# PRUSS1_UART register map
Vendor: Texas Instruments
Peripheral module from a debugger description file (folder DRA72x).
Registers are 32-bit, access per field, reset values left out (the file's numbers can be read two ways) unless marked. A register's access mark holds for its fields unless they carry their own. Offsets are as the file gives them; lines under a group give offsets from that group; [hi:lo] are bit positions; {n}, {i} and the like mark numbered series; 'fields as' and 'values as' point back to an identical list; <NAME> marks a mode.

## PRUSS1_UART
0x00 PRUSS_UART_RBR_THR_REGISTERS — In the non-FIFO mode, when a character is placed in Receiver buffer register and the receiver data-ready interrupt is enabled (DR = 1 in Interrupt identification register), an interrupt is generated. This interrupt is cleared when the character is read from Receiver buffer register. In the FIFO mode, the interrupt is generated when the FIFO is filled to the trigger level selected in the FIFO control register, and it is cleared when the FIFO contents drop below the trigger level. In the non-FIFO mode, if Transmitter holding register is empty and the THR empty (THRE) interrupt is enabled (ETBEI = 1 in Interrupt enable register), an interrupt is generated. This interrupt is cleared when a character is loaded into Transmitter holding register or the Interrupt identification register is read. In the FIFO mode, the interrupt is generated when the transmitter FIFO is empty, and it is cleared when at least one byte is loaded into the FIFO or Interrupt identification register is read.
  [7:0] DATA rw — Read: Read Receive Buffer RegisterWrite: Write Transmitter Holding Register .
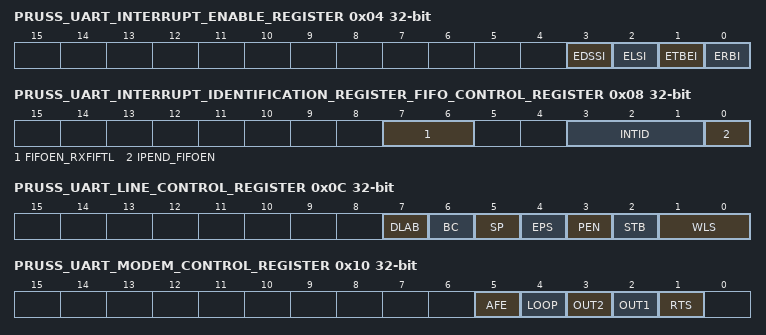
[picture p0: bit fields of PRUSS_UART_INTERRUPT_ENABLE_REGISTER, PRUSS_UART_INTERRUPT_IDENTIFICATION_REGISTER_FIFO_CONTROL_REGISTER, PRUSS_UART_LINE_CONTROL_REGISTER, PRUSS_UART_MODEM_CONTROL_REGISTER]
0x04 PRUSS_UART_INTERRUPT_ENABLE_REGISTER — The Interrupt enable register is used to individually enable or disable each type of interrupt request that can be generated by the UART. Each interrupt request that is enabled in Interrupt enable register is forwarded to the CPU.
  [3] EDSSI rw — Enable Modem Status Interrupt
  [2] ELSI rw — Receiver line status interrupt enable.
    0=DIS (Receiver line status interrupt is disabled.); 1=EN (Receiver line status interrupt is enabled.)
  [1] ETBEI rw — Transmitter holding register empty interrupt enable.
    0=DIS (Transmitter holding register empty interrupt is disabled.); 1=EN (Transmitter holding register empty interrupt is enabled.)
  [0] ERBI rw — Receiver data available interrupt and character timeout indication interrupt enable.
    0=DIS (Receiver data available interrupt and character timeout indication interrupt is disabled.); 1=EN (Receiver data available interrupt and character timeout indication interrupt is enabled.)
0x08 PRUSS_UART_INTERRUPT_IDENTIFICATION_REGISTER_FIFO_CONTROL_REGISTER — The Interrupt identification register is a read-only register at the same address as the FIFO control register, which is a write-only register. When an interrupt is generated and enabled in the Interrupt enable register, Interrupt identification register indicates that an interrupt is pending in the IPEND bit and encodes the type of interrupt in the INTID bits. Reading Interrupt identification register clears any THR empty (THRE) interrupts that are pending. The FIFOEN bit in Interrupt identification register can be checked to determine whether the UART is in the FIFO mode or the non-FIFO mode. Use FIFO control register to enable and clear the FIFOs and to select the receiver FIFO trigger level. The FIFOEN bit in FIFO control register must be set to 1 before other FIFO control register bits are written to or the FIFO control register bits are not programmed.
  [7:6] FIFOEN_RXFIFTL rw — Read: FIFOs enabled.0x1-0x2: Reserved . Write: Receiver FIFO trigger level. RXFIFTL sets the trigger level for the receiver FIFO. When the trigger level is reached, a receiver data-ready interrupt is generated (if the interrupt request is enabled). Once the FIFO drops below the trigger level, the interrupt is cleared. .
    0=Non-FIFO_mode; 3=FIFOEN_FIFO_(FCR)_3 (FIFOs are enabled. FIFOEN bit in the FIFO control register (FCR) is set to 1.); 0=1_byte; 1=4_bytes; 2=8_bytes; 3=14_bytes
  [3:1] INTID rw — Read: Interrupt type. See .0x4-0x5: Reserved . Write: . Bit 3: DMAMODE1: DMA MODE1 enable if FIFOs are enabled. Always write 1 to DMAMODE1. After a hardware reset, change DMAMODE1 from 0 to 1. DMAMODE1 = 1 is a requirement for proper communication between the UART and the EDMA controller. . Bit 2: TXCLR: Transmitter FIFO clear. Write a 1 to TXCLR to clear the bit. . Bit 1: RXCLR: Receiver FIFO clear. Write a 1 to RXCLR to clear the bit. .
    1=Transmitter holding register empty (priority 3); 2=Receiver_data_available_(priority_2); 3=Receiver line status (priority 1, highest); 6=Character timeout indication (priority 2); 0=DIS (DMA MODE1 is disabled.); 1=EN (DMA MODE1 is enabled.); 0=No_effect; 1=FIFO_FIFO_1 (Clears transmitter FIFO and resets the transmitter FIFO counter. The shift register is not cleared.); 0=No_effect; 1=FIFO_FIFO_1 (Clears receiver FIFO and resets the receiver FIFO counter. The shift register is not cleared.)
  [0] IPEND_FIFOEN rw — Read: Interrupt pending. When any UART interrupt is generated and is enabled in IER, IPEND is forced to 0. IPEND remains 0 until all pending interrupts are cleared or until a hardware reset occurs. If no interrupts are enabled, IPEND is never forced to 0.Write: Transmitter and receiver FIFOs mode enable. FIFOEN must be set before other FCR bits are written to or the FCR bits are not programmed. Clearing this bit clears the FIFO counters. .
    0=Interrupts_pending; 1=No_interrupts_pending; 0=FIFO_0 (Non-FIFO mode. The transmitter and receiver FIFOs are disabled, and the FIFO pointers are cleared.); 1=FIFO_1 (FIFO mode. The transmitter and receiver FIFOs are enabled.)
0x0C PRUSS_UART_LINE_CONTROL_REGISTER — The system programmer controls the format of the asynchronous data communication exchange by using Line control register. In addition, the programmer can retrieve, inspect, and modify the content of line control register; this eliminates the need for separate storage of the line characteristics in system memory.
  [7] DLAB rw — Divisor latch access bit. The divisor latch registers (DLL and DLH) can be accessed at dedicated addresses or at addresses shared by RBR, THR, and IER. Using the shared addresses requires toggling DLAB to change which registers are selected. If you use the dedicated addresses, you can keep DLAB = 0.
    0=(RBR),_(THR),_(IER)_RBR,_THR,_DLL,_CPU_RBR_THR._IER_DLH,_CPU_IER._0 (Allows access to the receiver buffer register (RBR), the transmitter holding register (THR), and the interrupt enable register (IER) selected. At the address shared by RBR, THR, and DLL, the CPU can read from RBR and write to THR. At the address shared by IER and DLH, the CPU can read from and write to IER.); 1=(DLL_DLH)._RBR,_THR,_DLL,_CPU_DLL._IER_DLH,_CPU_DLH._1 (Allows access to the divisor latches of the baud generator during a read or write operation (DLL and DLH). At the address shared by RBR, THR, and DLL, the CPU can read from and write to DLL. At the address shared by IER and DLH, the CPU can read from and write to DLH.)
  [6] BC rw — Break control.
    0=DIS (Break condition is disabled.); 1=EN (Break condition is transmitted to the receiving UART. A break condition is a condition where the UARTn_TXD signal is forced to the spacing (cleared) state.)
  [5] SP rw — Stick parity. The SP bit works in conjunction with the EPS and PEN bits. The relationship between the SP, EPS, and PEN bits is summarized in.
    0=DIS (Stick parity is disabled.); 1=EN (Stick parity is enabled.)
  [4] EPS rw — Even parity select. Selects the parity when parity is enabled (PEN = 1). The EPS bit works in conjunction with the SP and PEN bits. The relationship between the SP, EPS, and PEN bits is summarized in.
    0=PARITY_0 (Odd parity is selected (an odd number of logic 1s is transmitted or checked in the data and PARITY bits).); 1=PARITY_1 (Even parity is selected (an even number of logic 1s is transmitted or checked in the data and PARITY bits).)
  [3] PEN rw — Parity enable. The PEN bit works in conjunction with the SP and EPS bits. The relationship between the SP, EPS, and PEN bits is summarized in.
    0=PARITY_0 (No PARITY bit is transmitted or checked.); 1=STOP_1 (Parity bit is generated in transmitted data and is checked in received data between the last data word bit and the first STOP bit.)
  [2] STB rw — Number of STOP bits generated. STB specifies 1, 1.5, or 2 STOP bits in each transmitted character. When STB = 1, the WLS bit determines the number of STOP bits. The receiver clocks only the first STOP bit, regardless of the number of STOP bits selected. The number of STOP bits generated is summarized in.
    0=1_STOP_bit_is_generated; 1=WLS_STOP_1 (WLS bit determines the number of STOP bits:)
  [1:0] WLS rw — Word length select. Number of bits in each transmitted or received serial character. When STB = 1, the WLS bit determines the number of STOP bits.
    {v}={v+5}_bits (v=0..3)
0x10 PRUSS_UART_MODEM_CONTROL_REGISTER — The Modem control register provides the ability to enable/disable the autoflow functions, and enable/disable the loopback function for diagnostic purposes.
  [5] AFE rw — Autoflow control enable. Autoflow control allows the and signals to provide handshaking between UARTs during data transfer. When AFE = 1, the RTS bit determines the autoflow control enabled. Note that all UARTs do not support this feature, see your device-specific data manual for supported features. If this feature is not available, this bit is reserved in this device and should be cleared to 0.
    0=DIS (Autoflow control is disabled.); 1=EN (Autoflow control is enabled:)
  [4] LOOP rw — Loop back mode enable. LOOP is used for the diagnostic testing using the loop back feature.
    0=DIS (Loop back mode is disabled.); 1=EN (Loop back mode is enabled. When LOOP is set, the following occur:)
  [3] OUT2 rw — OUT2 Control Bit
  [2] OUT1 rw — OUT1 Control Bit
  [1] RTS rw — RTS control. When AFE = 1, the RTS bit determines the autoflow control enabled. Note that all UARTs do not support this feature, see your device-specific data manual for supported features. If this feature is not available, this bit is reserved in this device and should be cleared to 0.
    0=DIS (UARTn_RTS is disabled, UARTn_CTS is only enabled.); 1=EN (UARTn_RTS and UARTn_CTS are enabled.)
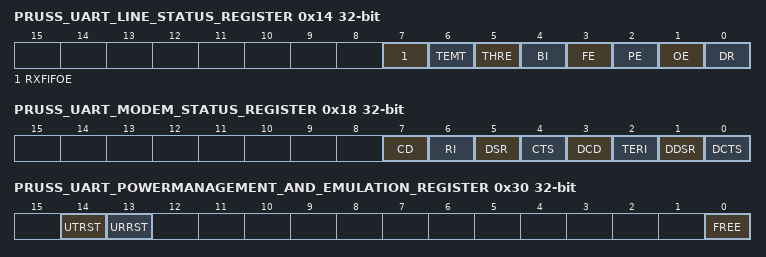
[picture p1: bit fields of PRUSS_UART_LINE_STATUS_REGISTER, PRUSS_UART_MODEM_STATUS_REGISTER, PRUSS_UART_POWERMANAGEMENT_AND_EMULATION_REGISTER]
0x14 PRUSS_UART_LINE_STATUS_REGISTER ro — The Line status register provides information to the CPU concerning the status of data transfers. Line status register is intended for read operations only; do not write to this register. Bits 1 through 4 record the error conditions that produce a receiver line status interrupt.
  [7] RXFIFOE — Receiver FIFO error. In non-FIFO mode:In FIFO mode: .
    0=RXFIFOE_CPU_(RBR)._0 (There has been no error, or RXFIFOE was cleared because the CPU read the erroneous character from the receiver buffer register (RBR).); 1=(RBR)._1 (There is a parity error, framing error, or break indicator in the receiver buffer register (RBR).); 0=RXFIFOE_CPU_FIFO_FIFO._0 (There has been no error, or RXFIFOE was cleared because the CPU read the erroneous character from the receiver FIFO and there are no more errors in the receiver FIFO.); 1=FIFO._1 (At least one parity error, framing error, or break indicator in the receiver FIFO.)
  [6] TEMT — Transmitter empty (TEMT) indicator. In non-FIFO mode:In FIFO mode: .
    0=(THR)_(TSR)_0 (Either the transmitter holding register (THR) or the transmitter shift register (TSR) contains a data character.); 1=(THR)_(TSR)_1 (Both the transmitter holding register (THR) and the transmitter shift register (TSR) are empty.); 0=FIFO_(TSR)_0 (Either the transmitter FIFO or the transmitter shift register (TSR) contains a data character.); 1=FIFO_(TSR)_1 (Both the transmitter FIFO and the transmitter shift register (TSR) are empty.)
  [5] THRE — Transmitter holding register empty (THRE) indicator. If the THRE bit is set and the corresponding interrupt enable bit is set (ETBEI = 1 in IER), an interrupt request is generated. In non-FIFO mode:In FIFO mode: .
    0=(THR)_THR_CPU._0 (Transmitter holding register (THR) is not empty. THR has been loaded by the CPU.); 1=(THR)_THR_(TSR)._1 (Transmitter holding register (THR) is empty (ready to accept a new character). The content of THR has been transferred to the transmitter shift register (TSR).); 0=FIFO_FIFO._FIFO_0 (Transmitter FIFO is not empty. At least one character has been written to the transmitter FIFO. You can write to the transmitter FIFO if it is not full.); 1=FIFO_FIFO_(TSR)._1 (Transmitter FIFO is empty. The last character in the FIFO has been transferred to the transmitter shift register (TSR).)
  [4] BI — Break indicator. The BI bit is set whenever the receive data input (UARTn_RXD) was held low for longer than a full-word transmission time. A full-word transmission time is defined as the total time to transmit the START, data, PARITY, and STOP bits. If the BI bit is set and the corresponding interrupt enable bit is set (ELSI = 1 in IER), an interrupt request is generated. In non-FIFO mode:In FIFO mode: .
    0=BI_CPU_(RBR)._0 (No break has been detected, or the BI bit was cleared because the CPU read the erroneous character from the receiver buffer register (RBR).); 1=A_(RBR)._1 (A break has been detected with the character in the receiver buffer register (RBR).); 0=BI_CPU_FIFO_FIFO_0 (No break has been detected, or the BI bit was cleared because the CPU read the erroneous character from the receiver FIFO and the next character to be read from the FIFO has no break indicator.); 1=A_FIFO._1 (A break has been detected with the character at the top of the receiver FIFO.)
  [3] FE — Framing error (FE) indicator. A framing error occurs when the received character does not have a valid STOP bit. In response to a framing error, the UART sets the FE bit and waits until the signal on the RX pin goes high. Once the RX signal goes high, the receiver is ready to detect a new START bit and receive new data. If the FE bit is set and the corresponding interrupt enable bit is set (ELSI = 1 in IER), an interrupt request is generated. In non-FIFO mode:In FIFO mode: .
    0=FE_CPU_(RBR)._0 (No framing error has been detected, or the FE bit was cleared because the CPU read the erroneous data from the receiver buffer register (RBR).); 1=A_(RBR)._1 (A framing error has been detected with the character in the receiver buffer register (RBR).); 0=FE_CPU_FIFO_FIFO_0 (No framing error has been detected, or the FE bit was cleared because the CPU read the erroneous data from the receiver FIFO and the next character to be read from the FIFO has no framing error.); 1=A_FIFO._1 (A framing error has been detected with the character at the top of the receiver FIFO.)
  [2] PE — Parity error (PE) indicator. A parity error occurs when the parity of the received character does not match the parity selected with the EPS bit in the line control register (LCR). If the PE bit is set and the corresponding interrupt enable bit is set (ELSI = 1 in IER), an interrupt request is generated. In non-FIFO mode:In FIFO mode: .
    0=PE_CPU_(RBR)._0 (No parity error has been detected, or the PE bit was cleared because the CPU read the erroneous data from the receiver buffer register (RBR).); 1=A_(RBR)._1 (A parity error has been detected with the character in the receiver buffer register (RBR).); 0=PE_CPU_FIFO_FIFO_0 (No parity error has been detected, or the PE bit was cleared because the CPU read the erroneous data from the receiver FIFO and the next character to be read from the FIFO has no parity error.); 1=A_FIFO._1 (A parity error has been detected with the character at the top of the receiver FIFO.)
  [1] OE — Overrun error (OE) indicator. An overrun error in the non-FIFO mode is different from an overrun error in the FIFO mode. If the OE bit is set and the corresponding interrupt enable bit is set (ELSI = 1 in IER), an interrupt request is generated. In non-FIFO mode:In FIFO mode: .
    0=OE_CPU_(LSR)._0 (No overrun error has been detected, or the OE bit was cleared because the CPU read the content of the line status register (LSR).); 1=(RBR)_RBR._1 (Overrun error has been detected. Before the character in the receiver buffer register (RBR) could be read, it was overwritten by the next character arriving in RBR.); 0=OE_CPU_(LSR)._0 (No overrun error has been detected, or the OE bit was cleared because the CPU read the content of the line status register (LSR).); 1=FIFO_FIFO_CPU_FIFO._1 (Overrun error has been detected. If data continues to fill the FIFO beyond the trigger level, an overrun error occurs only after the FIFO is full and the next character has been completely received in the shift register. An overrun error is indicated to the CPU as soon as it happens. The new character overwrites the character in the shift register, but it is not transferred to the FIFO.)
  [0] DR — Data-ready (DR) indicator for the receiver. If the DR bit is set and the corresponding interrupt enable bit is set (ERBI = 1 in IER), an interrupt request is generated. In non-FIFO mode:In FIFO mode: .
    0=DR_(RBR)._0 (Data is not ready, or the DR bit was cleared because the character was read from the receiver buffer register (RBR).); 1=A_(RBR)._1 (Data is ready. A complete incoming character has been received and transferred into the receiver buffer register (RBR).); 0=DR_FIFO_0 (Data is not ready, or the DR bit was cleared because all of the characters in the receiver FIFO have been read.); 1=FIFO._FIFO_DR_FIFO._DR_FIFO_1 (Data is ready. There is at least one unread character in the receiver FIFO. If the FIFO is empty, the DR bit is set as soon as a complete incoming character has been received and transferred into the FIFO. The DR bit remains set until the FIFO is empty again.)
0x18 PRUSS_UART_MODEM_STATUS_REGISTER ro — The Modem status register provides information to the CPU concerning the status of modem control signals. Modem status register is intended for read operations only; do not write to this register.
  [7] CD — Complement of the Carrier Detect input. When the UART is in the diagnostic test mode (loopback mode MCR[4] = 1), this bit is equal to the MCR bit 3 (OUT2).
  [6] RI — Complement of the Ring Indicator input. When the UART is in the diagnostic test mode (loopback mode MCR[4] = 1), this bit is equal to the MCR bit 2 (OUT1).
  [5] DSR — Complement of the Data Set Ready input. When the UART is in the diagnostic test mode (loopback mode MCR[4] = 1), this bit is equal to the MCR bit 0 (DTR).
  [4] CTS — Complement of the Clear To Send input. When the UART is in the diagnostic test mode (loopback mode MCR[4] = 1), this bit is equal to the MCR bit 1 (RTS).
  [3] DCD — Change in DCD indicator bit. DCD indicates that the DCD input has changed state since the last time it was read by the CPU. When DCD is set and the modem status interrupt is enabled, a modem status interrupt is generated.
  [2] TERI — Trailing edge of RI (TERI) indicator bit. TERI indicates that the RI input has changed from a low to a high. When TERI is set and the modem status interrupt is enabled, a modem status interrupt is generated.
  [1] DDSR — Change in DSR indicator bit. DDSR indicates that the DSR input has changed state since the last time it was read by the CPU. When DDSR is set and the modem status interrupt is enabled, a modem status interrupt is generated.
  [0] DCTS — Change in CTS indicator bit. DCTS indicates that the CTS input has changed state since the last time it was read by the CPU. When DCTS is set (autoflow control is not enabled and the modem status interrupt is enabled), a modem status interrupt is generated. When autoflow control is enabled, no interrupt is generated.
0x1C PRUSS_UART_SCRATCH_REGISTER ro — The Scratch Pad register is intended for programmer's use as a scratch pad. It temporarily holds the programmer's data without affecting UART operation.
  [7:0] SCR — These bits are intended for the programmer's use as a scratch pad in the sense that it temporarily holds the programmer's data without affecting any other UART operation.
0x20 PRUSS_UART_DIVISOR_REGISTER_LSB_ — Two 8-bit register fields (DLL and DLH), called divisor latches, store the 16-bit divisor for generation of the baud clock in the baud generator. DLH holds the most-significant bits of the divisor, and DLL holds the least-significant bits of the divisor. These divisor latches must be loaded during initialization of the UART in order to ensure desired operation of the baud generator. Writing to the divisor latches results in two wait states being inserted during the write access while the baud generator is loaded with the new value.
  [7:0] DLL rw — The 8 least-significant bits (LSBs) of the 16-bit divisor for generation of the baud clock in the baud rate generator.
0x24 PRUSS_UART_DIVISOR_REGISTER_MSB_ — Two 8-bit register fields (DLL and DLH), called divisor latches, store the 16-bit divisor for generation of the baud clock in the baud generator. DLH holds the most-significant bits of the divisor, and DLL holds the least-significant bits of the divisor. These divisor latches must be loaded during initialization of the UART in order to ensure desired operation of the baud generator. Writing to the divisor latches results in two wait states being inserted during the write access while the baud generator is loaded with the new value.
  [7:0] DLH rw — The 8 most-significant bits (MSBs) of the 16-bit divisor for generation of the baud clock in the baud rate generator.
0x28 PRUSS_UART_PERIPHERAL_ID_REGISTER ro — Peripheral Identification register
  [31:0] PID
0x30 PRUSS_UART_POWERMANAGEMENT_AND_EMULATION_REGISTER — Power and emulation management register
  [14] UTRST rw — UART transmitter reset. Resets and enables the transmitter.
    0=DIS (Transmitter is disabled and in reset state.); 1=Transmitter_is_enabled
  [13] URRST rw — UART receiver reset. Resets and enables the receiver.
    0=DIS (Receiver is disabled and in reset state.); 1=EN (Receiver is enabled.)
  [0] FREE rw — Free-running enable mode bit. This bit determines the emulation mode functionality of the UART. When halted, the UART can handle register read/write requests, but does not generate any transmission/reception, interrupts or events.
    0=UART_UART_0 (If a transmission is not in progress, the UART halts immediately. If a transmission is in progress, the UART halts after completion of the one-word transmission.); 1=UART_1 (Free-running mode is enabled; UART continues to run normally.)
0x34 PRUSS_UART_MODE_DEFINITION_REGISTER — The Mode definition register determines the over-sampling mode for the UART.
  [0] OSM_SEL rw — Over-Sampling Mode Select.
    0=16×_over-sampling; 1=13×_over-sampling
